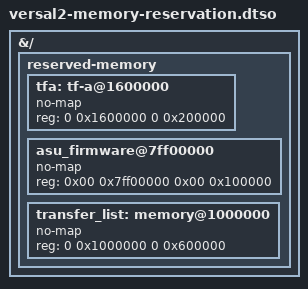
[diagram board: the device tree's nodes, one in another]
// SPDX-License-Identifier: BSD-2-Clause
/*
 * Copyright (C) 2024, Advanced Micro Devices, Inc.
 *
 */

/dts-v1/;
/plugin/;

&{/} {
	reserved-memory {
		#address-cells = <2>;
		#size-cells = <2>;

		tfa: tf-a@1600000 {
			no-map;
			reg = <0 0x1600000 0 0x200000>;
		};

		asu_firmware@7ff00000 {
			no-map;
			reg = <0x00 0x7ff00000 0x00 0x100000>;
		};

		transfer_list: memory@1000000 {
			no-map;
			reg = <0 0x1000000 0 0x600000>;
		};
	};
};
